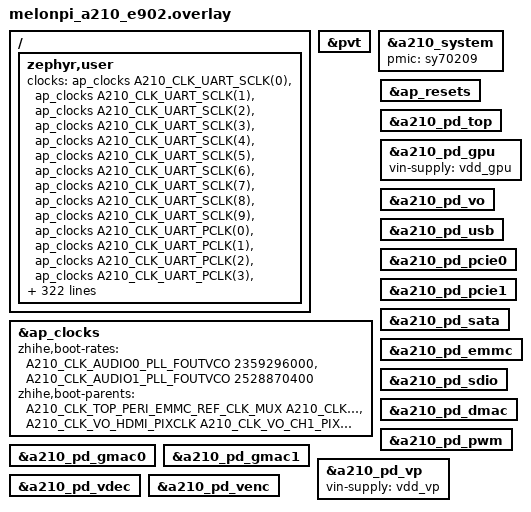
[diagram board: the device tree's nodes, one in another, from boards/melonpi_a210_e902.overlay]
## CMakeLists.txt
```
# SPDX-License-Identifier: Apache-2.0
cmake_minimum_required(VERSION 3.20.0)
find_package(Zephyr REQUIRED HINTS $ENV{ZEPHYR_BASE})
project(scmi_server)
target_sources(app PRIVATE src/main.c)
if(CONFIG_CLOCK_CONTROL_A210)
  target_sources(app PRIVATE src/a210_resources.c)
else()
  target_sources(app PRIVATE src/resources.c)
endif()
```

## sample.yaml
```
sample:
  name: SCMI platform server
tests:
  sample.subsys.scmi_server:
    build_only: true
    platform_allow:
      - light_val_a/th1520/e902
      - beaglev_ahead/th1520/e902
      - milkv_meles/th1520/e902
      - licheepi_4a/th1520/e902
      - melonpi/a210/e902
    tags: [scmi, regulator]
  sample.subsys.scmi_server.base:
    build_only: true
    platform_allow: [beaglev_ahead/th1520/e902]
    extra_configs: [CONFIG_SCMI_SERVER_VOLTAGE=n]
    tags: [scmi]
```

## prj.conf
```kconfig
CONFIG_MULTITHREADING=n
CONFIG_SYS_CLOCK_EXISTS=n
CONFIG_TIMESLICING=n
CONFIG_CONSOLE=n
CONFIG_SERIAL=n
CONFIG_PRINTK=n
CONFIG_BOOT_BANNER=n
CONFIG_LOG=n
CONFIG_ASSERT=y
CONFIG_ASSERT_MODULE_DEFAULT_LEVEL_NORMAL=y
CONFIG_DEVICE_API_ASSERT=n
CONFIG_MINIMAL_LIBC=y
CONFIG_SIZE_OPTIMIZATIONS=y
CONFIG_ISR_STACK_SIZE=4096
CONFIG_MAIN_STACK_SIZE=4096
CONFIG_HEAP_MEM_POOL_SIZE=0
CONFIG_BUILD_OUTPUT_BIN=y
CONFIG_BUILD_OUTPUT_HEX=n
CONFIG_COUNTER=y
CONFIG_I2C=y
CONFIG_REGULATOR=y
CONFIG_MBOX=y
CONFIG_SCMI_SERVER=y
CONFIG_SCMI_SERVER_PERFORMANCE=y
CONFIG_CLOCK_CONTROL=y
```

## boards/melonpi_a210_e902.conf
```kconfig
# SPDX-License-Identifier: Apache-2.0
CONFIG_SCMI_SERVER_CLOCK=y
CONFIG_SCMI_SERVER_RESET=y
CONFIG_RESET=y
CONFIG_POWER_DOMAIN=y
CONFIG_PM_DEVICE=y
CONFIG_SCMI_SERVER_POWER=y
CONFIG_SENSOR=y
CONFIG_SCMI_SERVER_SENSOR=y
CONFIG_SCMI_SERVER_SYSTEM_POWER=y
# Measured peaks on Melon Pi: 1024 bytes main, 32 bytes interrupt stack,
# from reset through Linux runtime, DVFS and power-domain tests.
CONFIG_MAIN_STACK_SIZE=2048
CONFIG_ISR_STACK_SIZE=1024
```

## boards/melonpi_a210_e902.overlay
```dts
/* SPDX-License-Identifier: Apache-2.0 */
#include <zephyr/dt-bindings/clock/zhihe-a210.h>
#include <zephyr/dt-bindings/reset/zhihe-a210.h>

&pvt {
	status = "okay";
};

&a210_system {
	pmic = <&sy70209>;
	status = "okay";
};

&ap_clocks {
	zhihe,boot-rates = <A210_CLK_AUDIO0_PLL_FOUTVCO 2359296000>,
			   <A210_CLK_AUDIO1_PLL_FOUTVCO 2528870400>;
	zhihe,boot-parents = <A210_CLK_TOP_PERI_EMMC_REF_CLK_MUX A210_CLK_AUDIO0_PLL_FOUTVCO>,
			     <A210_CLK_VO_HDMI_PIXCLK A210_CLK_VO_CH1_PIXCLK_EN>;
	status = "okay";
};

&ap_resets {
	status = "okay";
};

/ {
	zephyr,user {
		clocks = <&ap_clocks A210_CLK_UART_SCLK(0)>,
			 <&ap_clocks A210_CLK_UART_SCLK(1)>,
			 <&ap_clocks A210_CLK_UART_SCLK(2)>,
			 <&ap_clocks A210_CLK_UART_SCLK(3)>,
			 <&ap_clocks A210_CLK_UART_SCLK(4)>,
			 <&ap_clocks A210_CLK_UART_SCLK(5)>,
			 <&ap_clocks A210_CLK_UART_SCLK(6)>,
			 <&ap_clocks A210_CLK_UART_SCLK(7)>,
			 <&ap_clocks A210_CLK_UART_SCLK(8)>,
			 <&ap_clocks A210_CLK_UART_SCLK(9)>,
			 <&ap_clocks A210_CLK_UART_PCLK(0)>,
			 <&ap_clocks A210_CLK_UART_PCLK(1)>,
			 <&ap_clocks A210_CLK_UART_PCLK(2)>,
			 <&ap_clocks A210_CLK_UART_PCLK(3)>,
			 <&ap_clocks A210_CLK_UART_PCLK(4)>,
			 <&ap_clocks A210_CLK_UART_PCLK(5)>,
			 <&ap_clocks A210_CLK_UART_PCLK(6)>,
			 <&ap_clocks A210_CLK_UART_PCLK(7)>,
			 <&ap_clocks A210_CLK_UART_PCLK(8)>,
			 <&ap_clocks A210_CLK_UART_PCLK(9)>,
			 <&ap_clocks A210_CLK_PERI1_PAD>,
			 <&ap_clocks A210_CLK_PERI2_PAD>,
			 <&ap_clocks A210_CLK_PERI3_PAD>,
			 <&ap_clocks A210_CLK_AON_SYS>,
			 <&ap_clocks A210_CLK_AON_I2C1_IC>,
			 <&ap_clocks A210_CLK_AON_I2C1_PCLK>,
			 <&ap_clocks A210_CLK_AUDIO0_PLL_FOUTVCO>,
			 <&ap_clocks A210_CLK_AUDIO1_PLL_FOUTVCO>,
			 <&ap_clocks A210_CLK_TOP_GPU_CORE_CLK_DIV>,
			 <&ap_clocks A210_CLK_TOP_PERI_EMMC_REF_CLK_DIV>,
			 <&ap_clocks A210_CLK_TOP_PERI_EMMC_REF_CLK_MUX>,
			 <&ap_clocks A210_CLK_SW_PWR_WRAP_GPU_SYS_CLK_EN>,
			 <&ap_clocks A210_CLK_SW_PWR_WRAP_DFMU_CORE_CLK_EN>,
			 <&ap_clocks A210_CLK_SW_PWR_WRAP_GPU_CORE_CLK_EN>,
			 <&ap_clocks A210_CLK_E16PHY_PCLK_EN>,
			 <&ap_clocks A210_CLK_SATA_MST_AFENCE_ACLK_EN>,
			 <&ap_clocks A210_CLK_SATA_SLV_AFENCE_ACLK_EN>,
			 <&ap_clocks A210_CLK_SATA_GEN3X2_ACLK_EN>,
			 <&ap_clocks A210_CLK_X2X_SATA_SLV_ACLK_EN>,
			 <&ap_clocks A210_CLK_X2X_SATA_MST_ACLK_EN>,
			 <&ap_clocks A210_CLK_SATA_RXOOB1_CLK_EN>,
			 <&ap_clocks A210_CLK_SATA_RXOOB0_CLK_EN>,
			 <&ap_clocks A210_CLK_SATA_PMALIVE_CLK_EN>,
			 <&ap_clocks A210_CLK_PCIE_DM_GEN3X4_AUX_CLK_EN>,
			 <&ap_clocks A210_CLK_PCIE_DM_GEN3X4_MST_ACLK_EN>,
			 <&ap_clocks A210_CLK_PCIE_DM_GEN3X4_PCLK_EN>,
			 <&ap_clocks A210_CLK_PCIE_DM_GEN3X4_SLV_ACLK_EN>,
			 <&ap_clocks A210_CLK_PCIE_RP_GEN3X1_AUX_CLK_EN>,
			 <&ap_clocks A210_CLK_PCIE_RP_GEN3X1_MST_ACLK_EN>,
			 <&ap_clocks A210_CLK_PCIE_RP_GEN3X1_PCLK_EN>,
			 <&ap_clocks A210_CLK_PCIE_RP_GEN3X1_SLV_ACLK_EN>,
			 <&ap_clocks A210_CLK_USB_SS_AXI_MST_PCLK_EN>,
			 <&ap_clocks A210_CLK_USB_SS_AXI_MST_ACLK_EN>,
			 <&ap_clocks A210_CLK_USB_SS_DFMU_IOMMU_PTW_ACLK_EN>,
			 <&ap_clocks A210_CLK_USB_SS_DFMU_ACLK_EN>,
			 <&ap_clocks A210_CLK_USB_SS_DFMU_PCLK_EN>,
			 <&ap_clocks A210_CLK_USB31_SLV_AFENCE_ACLK_EN>,
			 <&ap_clocks A210_CLK_USB31_REF_CLK_EN>,
			 <&ap_clocks A210_CLK_USB31_SUSPEND_CLK_EN>,
			 <&ap_clocks A210_CLK_USB31_BUS_CLK_EN>,
			 <&ap_clocks A210_CLK_USB31_PCLK_EN>,
			 <&ap_clocks A210_CLK_C10PHY_SUSPEND_CLK_EN>,
			 <&ap_clocks A210_CLK_C10PHY_PCLK_EN>,
			 <&ap_clocks A210_CLK_VO_X2H1_CLK_EN>,
			 <&ap_clocks A210_CLK_VO_X2H0_CLK_EN>,
			 <&ap_clocks A210_CLK_VO_PTW_ACLK_EN>,
			 <&ap_clocks A210_CLK_VO_DFMU_ACLK_EN>,
			 <&ap_clocks A210_CLK_VO_DFMU_PCLK_EN>,
			 <&ap_clocks A210_CLK_VO_ARB_ACLK_EN>,
			 <&ap_clocks A210_CLK_VO_ARB_PCLK_EN>,
			 <&ap_clocks A210_CLK_VO_HDMI_SFRCLK_EN>,
			 <&ap_clocks A210_CLK_VO_CEC_CLK_EN>,
			 <&ap_clocks A210_CLK_VO_HDMI_PCLK_EN>,
			 <&ap_clocks A210_CLK_VO_DPU_ACLK_EN>,
			 <&ap_clocks A210_CLK_VO_DPUC_CLK_EN>,
			 <&ap_clocks A210_CLK_VO_DPU_HCLK_EN>,
			 <&ap_clocks A210_CLK_VO_CH1_PIXCLK_EN>,
			 <&ap_clocks A210_CLK_VO_CH0_PIXCLK_EN>,
			 <&ap_clocks A210_CLK_PERI0_MBOX1_PCLK_EN>,
			 <&ap_clocks A210_CLK_PERI0_MBOX0_PCLK_EN>,
			 <&ap_clocks A210_CLK_PERI0_WDT0_PCLK_EN>,
			 <&ap_clocks A210_CLK_PERI0_TIMER1_PCLK_EN>,
			 <&ap_clocks A210_CLK_PERI0_TIMER1_CCLK_EN>,
			 <&ap_clocks A210_CLK_PERI0_TIMER0_PCLK_EN>,
			 <&ap_clocks A210_CLK_PERI0_TIMER0_CCLK_EN>,
			 <&ap_clocks A210_CLK_PERI1_SPI0_SSI_CLK_EN>,
			 <&ap_clocks A210_CLK_PERI1_SPI0_PCLK_EN>,
			 <&ap_clocks A210_CLK_PERI1_QSPI0_SSI_CLK_EN>,
			 <&ap_clocks A210_CLK_PERI1_QSPI0_PCLK_EN>,
			 <&ap_clocks A210_CLK_PERI1_PWM0_CCLK_EN>,
			 <&ap_clocks A210_CLK_PERI1_I2C2_PCLK_EN>,
			 <&ap_clocks A210_CLK_PERI1_I2C2_IC_CLK_EN>,
			 <&ap_clocks A210_CLK_PERI1_I2C1_PCLK_EN>,
			 <&ap_clocks A210_CLK_PERI1_I2C1_IC_CLK_EN>,
			 <&ap_clocks A210_CLK_PERI1_I2C0_PCLK_EN>,
			 <&ap_clocks A210_CLK_PERI1_I2C0_IC_CLK_EN>,
			 <&ap_clocks A210_CLK_PERI1_GPIO1_PCLK_EN>,
			 <&ap_clocks A210_CLK_PERI1_GPIO1_DBCLK_EN>,
			 <&ap_clocks A210_CLK_PERI1_GPIO0_PCLK_EN>,
			 <&ap_clocks A210_CLK_PERI1_GPIO0_DBCLK_EN>,
			 <&ap_clocks A210_CLK_PERI1_GMAC1_HCLK_EN>,
			 <&ap_clocks A210_CLK_PERI1_GMAC1_ACLK_EN>,
			 <&ap_clocks A210_CLK_PERI1_GMAC0_HCLK_EN>,
			 <&ap_clocks A210_CLK_PERI1_GMAC0_ACLK_EN>,
			 <&ap_clocks A210_CLK_PERI2_I2S1_PCLK_EN>,
			 <&ap_clocks A210_CLK_PERI2_I2S1_SRC_CLK_EN>,
			 <&ap_clocks A210_CLK_PERI2_I2C7_IC_CLK_EN>,
			 <&ap_clocks A210_CLK_PERI2_I2C7_PCLK_EN>,
			 <&ap_clocks A210_CLK_PERI2_I2C6_IC_CLK_EN>,
			 <&ap_clocks A210_CLK_PERI2_I2C6_PCLK_EN>,
			 <&ap_clocks A210_CLK_PERI2_I2C5_IC_CLK_EN>,
			 <&ap_clocks A210_CLK_PERI2_I2C5_PCLK_EN>,
			 <&ap_clocks A210_CLK_PERI2_I2C4_IC_CLK_EN>,
			 <&ap_clocks A210_CLK_PERI2_I2C4_PCLK_EN>,
			 <&ap_clocks A210_CLK_PERI2_I2C3_IC_CLK_EN>,
			 <&ap_clocks A210_CLK_PERI2_I2C3_PCLK_EN>,
			 <&ap_clocks A210_CLK_PERI2_GPIO3_DBCLK_EN>,
			 <&ap_clocks A210_CLK_PERI2_GPIO3_PCLK_EN>,
			 <&ap_clocks A210_CLK_PERI2_SPI1_PCLK_EN>,
			 <&ap_clocks A210_CLK_PERI2_GPIO2_PCLK_EN>,
			 <&ap_clocks A210_CLK_PERI2_SPI1_SSI_CLK_EN>,
			 <&ap_clocks A210_CLK_PERI2_GPIO2_DBCLK_EN>,
			 <&ap_clocks A210_CLK_PERI2_QSPI1_PCLK_EN>,
			 <&ap_clocks A210_CLK_PERI2_QSPI1_SSI_CLK_EN>,
			 <&ap_clocks A210_CLK_PERI2_PWM2_CCLK_EN>,
			 <&ap_clocks A210_CLK_PERI2_PWM1_CCLK_EN>,
			 <&ap_clocks A210_CLK_PERI3_GPIO4_PCLK_EN>,
			 <&ap_clocks A210_CLK_PERI3_GPIO4_DBCLK_EN>,
			 <&ap_clocks A210_CLK_PERI3_ADC_PCLK_EN>,
			 <&ap_clocks A210_CLK_AXI_PERI3_MST_PCLK_EN>,
			 <&ap_clocks A210_CLK_AXI_PERI3_MST_ACLK_EN>,
			 <&ap_clocks A210_CLK_PERI3_SDIO_X2X_ACLK_S_EN>,
			 <&ap_clocks A210_CLK_PERI3_SDIO_X2X_ACLK_M_EN>,
			 <&ap_clocks A210_CLK_PERI3_SDIO_OSC_CLK_EN>,
			 <&ap_clocks A210_CLK_PERI3_SDIO_HCLK_EN>,
			 <&ap_clocks A210_CLK_PERI3_EMMC_X2X_ACLK_S_EN>,
			 <&ap_clocks A210_CLK_PERI3_EMMC_X2X_ACLK_M_EN>,
			 <&ap_clocks A210_CLK_PERI3_EMMC_OSC_CLK_EN>,
			 <&ap_clocks A210_CLK_PERI3_EMMC_HCLK_EN>,
			 <&ap_clocks A210_CLK_PERI3_EMMC_ACLK_EN>,
			 <&ap_clocks A210_CLK_PERI3_EMMC_SDIO_REF_CLK_CG_EN>,
			 <&ap_clocks A210_CLK_PERI3_DMAC_HCLK_EN>,
			 <&ap_clocks A210_CLK_PERI3_DMAC_ACLK_EN>,
			 <&ap_clocks A210_CLK_TEE_DMAC_CLKEN>,
			 <&ap_clocks A210_CLK_USB20_BUS_CLK>,
			 <&ap_clocks A210_CLK_PERI3_SDIO_ACLK_EN>,
			 <&ap_clocks A210_CLK_PERI1_X2H_GMAC1_HCLK_EN>,
			 <&ap_clocks A210_CLK_PERI1_X2H_GMAC1_ACLK_EN>,
			 <&ap_clocks A210_CLK_PERI1_X2H_GMAC0_HCLK_EN>,
			 <&ap_clocks A210_CLK_PERI1_X2H_GMAC0_ACLK_EN>,
			 <&ap_clocks A210_CLK_VO_HDMI_PIXCLK>,
			 <&ap_clocks A210_CLK_USB20_X2H_HCLK>,
			 <&ap_clocks A210_CLK_USB20_X2H_ACLK>,
			 <&ap_clocks A210_CLK_USB20_SLV_AFENCE_ACLK>,
			 <&ap_clocks A210_CLK_USB20_H2P_HCLK>,
			 <&ap_clocks A210_CLK_USB20_AHB_SLV_HCLK>,
			 <&ap_clocks A210_CLK_USB20_SYSREG_PCLK>,
			 <&ap_clocks A210_CLK_USB20_WRAP0_HCLK>,
			 <&ap_clocks A210_CLK_USB20_WRAP1_HCLK>,
			 <&ap_clocks A210_CLK_USB20_A2X0_HCLK>,
			 <&ap_clocks A210_CLK_USB20_A2X0_ACLK>,
			 <&ap_clocks A210_CLK_USB20_A2X1_HCLK>,
			 <&ap_clocks A210_CLK_USB20_A2X1_ACLK>,
			 <&ap_clocks A210_CLK_VP_VDEC_ACLK_EN>,
			 <&ap_clocks A210_CLK_VP_VDEC_CCLK_EN>,
			 <&ap_clocks A210_CLK_VP_VDEC_PCLK_EN>,
			 <&ap_clocks A210_CLK_VP_VENC_ACLK_EN>,
			 <&ap_clocks A210_CLK_VP_VENC_CCLK_EN>,
			 <&ap_clocks A210_CLK_VP_VENC_PCLK_EN>;
		resets = <&ap_resets A210_RESET_UART_SRST(0)>,
			 <&ap_resets A210_RESET_UART_SRST(1)>,
			 <&ap_resets A210_RESET_UART_SRST(2)>,
			 <&ap_resets A210_RESET_UART_SRST(3)>,
			 <&ap_resets A210_RESET_UART_SRST(4)>,
			 <&ap_resets A210_RESET_UART_SRST(5)>,
			 <&ap_resets A210_RESET_UART_SRST(6)>,
			 <&ap_resets A210_RESET_UART_SRST(7)>,
			 <&ap_resets A210_RESET_UART_SRST(8)>,
			 <&ap_resets A210_RESET_UART_SRST(9)>,
			 <&ap_resets A210_RESET_UART_PRST(0)>,
			 <&ap_resets A210_RESET_UART_PRST(1)>,
			 <&ap_resets A210_RESET_UART_PRST(2)>,
			 <&ap_resets A210_RESET_UART_PRST(3)>,
			 <&ap_resets A210_RESET_UART_PRST(4)>,
			 <&ap_resets A210_RESET_UART_PRST(5)>,
			 <&ap_resets A210_RESET_UART_PRST(6)>,
			 <&ap_resets A210_RESET_UART_PRST(7)>,
			 <&ap_resets A210_RESET_UART_PRST(8)>,
			 <&ap_resets A210_RESET_UART_PRST(9)>,
			 <&ap_resets A210_RESET_PERI1_PAD>,
			 <&ap_resets A210_RESET_PERI2_PAD>,
			 <&ap_resets A210_RESET_PERI3_PAD>,
			 <&ap_resets A210_RESET_AON_I2C1>,
			 <&ap_resets A210_RESET_GPU_PWR_WRAP_RGX_HOOD_RST>,
			 <&ap_resets A210_RESET_PCIE_DM_GEN3X4_APBS_PRST>,
			 <&ap_resets A210_RESET_PCIE_DM_GEN3X4_POWER_UP_RST>,
			 <&ap_resets A210_RESET_PCIE_E16PHY_APBS_PRST>,
			 <&ap_resets A210_RESET_PCIE_E16PHY_PHY_RST>,
			 <&ap_resets A210_RESET_PCIE_RP_GEN3X1_APBS_PRST>,
			 <&ap_resets A210_RESET_PCIE_RP_GEN3X1_POWER_UP_RST>,
			 <&ap_resets A210_RESET_PCIE_SATA_ARESET>,
			 <&ap_resets A210_RESET_PCIE_SATA_MST_AFENCE_ARST>,
			 <&ap_resets A210_RESET_PCIE_SATA_RST_ASIC0>,
			 <&ap_resets A210_RESET_PCIE_SATA_RST_ASIC1>,
			 <&ap_resets A210_RESET_PCIE_SATA_RST_PMALIVE>,
			 <&ap_resets A210_RESET_PCIE_SATA_RST_RXOOB0>,
			 <&ap_resets A210_RESET_PCIE_SATA_RST_RXOOB1>,
			 <&ap_resets A210_RESET_PCIE_SATA_SLV_AFENCE_ARST>,
			 <&ap_resets A210_RESET_PCIE_X2X_SATA_MST_ARST>,
			 <&ap_resets A210_RESET_PCIE_X2X_SATA_SLV_ARST>,
			 <&ap_resets A210_RESET_PERI0_TIMER0_CRST>,
			 <&ap_resets A210_RESET_PERI0_TIMER0_PRST>,
			 <&ap_resets A210_RESET_PERI0_TIMER1_CRST>,
			 <&ap_resets A210_RESET_PERI0_TIMER1_PRST>,
			 <&ap_resets A210_RESET_PERI0_WDT0_PRST>,
			 <&ap_resets A210_RESET_PERI1_GMAC0_ARST>,
			 <&ap_resets A210_RESET_PERI1_GMAC0_HRST>,
			 <&ap_resets A210_RESET_PERI1_GMAC0_X2H_ARST>,
			 <&ap_resets A210_RESET_PERI1_GMAC0_X2H_HRST>,
			 <&ap_resets A210_RESET_PERI1_GMAC1_ARST>,
			 <&ap_resets A210_RESET_PERI1_GMAC1_HRST>,
			 <&ap_resets A210_RESET_PERI1_GMAC1_X2H_ARST>,
			 <&ap_resets A210_RESET_PERI1_GMAC1_X2H_HRST>,
			 <&ap_resets A210_RESET_PERI1_GPIO0_DBRST>,
			 <&ap_resets A210_RESET_PERI1_GPIO0_PRST>,
			 <&ap_resets A210_RESET_PERI1_GPIO1_DBRST>,
			 <&ap_resets A210_RESET_PERI1_GPIO1_PRST>,
			 <&ap_resets A210_RESET_PERI1_I2C0_IC_RST>,
			 <&ap_resets A210_RESET_PERI1_I2C0_PRST>,
			 <&ap_resets A210_RESET_PERI1_I2C1_IC_RST>,
			 <&ap_resets A210_RESET_PERI1_I2C1_PRST>,
			 <&ap_resets A210_RESET_PERI1_I2C2_IC_RST>,
			 <&ap_resets A210_RESET_PERI1_I2C2_PRST>,
			 <&ap_resets A210_RESET_PERI1_PWM0_CRST>,
			 <&ap_resets A210_RESET_PERI1_PWM0_PRST>,
			 <&ap_resets A210_RESET_PERI1_QSPI0_PRST>,
			 <&ap_resets A210_RESET_PERI1_QSPI0_SSI_RST>,
			 <&ap_resets A210_RESET_PERI1_SPI0_PRST>,
			 <&ap_resets A210_RESET_PERI1_SPI0_SSI_RST>,
			 <&ap_resets A210_RESET_PERI2_GPIO2_DBRST>,
			 <&ap_resets A210_RESET_PERI2_GPIO2_PRST>,
			 <&ap_resets A210_RESET_PERI2_GPIO3_DBRST>,
			 <&ap_resets A210_RESET_PERI2_GPIO3_PRST>,
			 <&ap_resets A210_RESET_PERI2_I2C3_IC_RST>,
			 <&ap_resets A210_RESET_PERI2_I2C3_PRST>,
			 <&ap_resets A210_RESET_PERI2_I2C4_IC_RST>,
			 <&ap_resets A210_RESET_PERI2_I2C4_PRST>,
			 <&ap_resets A210_RESET_PERI2_I2C5_IC_RST>,
			 <&ap_resets A210_RESET_PERI2_I2C5_PRST>,
			 <&ap_resets A210_RESET_PERI2_I2C6_IC_RST>,
			 <&ap_resets A210_RESET_PERI2_I2C6_PRST>,
			 <&ap_resets A210_RESET_PERI2_I2C7_IC_RST>,
			 <&ap_resets A210_RESET_PERI2_I2C7_PRST>,
			 <&ap_resets A210_RESET_PERI2_I2S1_PRST>,
			 <&ap_resets A210_RESET_PERI2_PWM1_CRST>,
			 <&ap_resets A210_RESET_PERI2_PWM1_PRST>,
			 <&ap_resets A210_RESET_PERI2_PWM2_CRST>,
			 <&ap_resets A210_RESET_PERI2_PWM2_PRST>,
			 <&ap_resets A210_RESET_PERI2_QSPI1_PRST>,
			 <&ap_resets A210_RESET_PERI2_QSPI1_SSI_RST>,
			 <&ap_resets A210_RESET_PERI2_SPI1_PRST>,
			 <&ap_resets A210_RESET_PERI2_SPI1_SSI_RST>,
			 <&ap_resets A210_RESET_PERI3_ADC_PRST>,
			 <&ap_resets A210_RESET_PERI3_DMAC_ARST>,
			 <&ap_resets A210_RESET_PERI3_DMAC_HRST>,
			 <&ap_resets A210_RESET_PERI3_EMMC_RST>,
			 <&ap_resets A210_RESET_PERI3_EMMC_X2X_ARST_M>,
			 <&ap_resets A210_RESET_PERI3_EMMC_X2X_ARST_S>,
			 <&ap_resets A210_RESET_PERI3_GPIO4_DBRST>,
			 <&ap_resets A210_RESET_PERI3_GPIO4_PRST>,
			 <&ap_resets A210_RESET_PERI3_SDIO_RST>,
			 <&ap_resets A210_RESET_PERI3_SDIO_X2X_ARST_M>,
			 <&ap_resets A210_RESET_PERI3_SDIO_X2X_ARST_S>,
			 <&ap_resets A210_RESET_TEE_DMAC_ARST>,
			 <&ap_resets A210_RESET_TEE_DMAC_HRST>,
			 <&ap_resets A210_RESET_USB_AXI4_MST_ARST>,
			 <&ap_resets A210_RESET_USB_AXI4_MST_PRST>,
			 <&ap_resets A210_RESET_USB_C10PHY_APBS_PRST>,
			 <&ap_resets A210_RESET_USB_C10PHY_PHY_RST>,
			 <&ap_resets A210_RESET_USB_DFMU_ARST>,
			 <&ap_resets A210_RESET_USB_DFMU_PRST>,
			 <&ap_resets A210_RESET_USB_USB20_BLK_A2X0_ARST>,
			 <&ap_resets A210_RESET_USB_USB20_BLK_A2X0_HRST>,
			 <&ap_resets A210_RESET_USB_USB20_BLK_A2X1_ARST>,
			 <&ap_resets A210_RESET_USB_USB20_BLK_A2X1_HRST>,
			 <&ap_resets A210_RESET_USB_USB20_BLK_AHB_SLV_HRST>,
			 <&ap_resets A210_RESET_USB_USB20_BLK_AXI_MST_ARST>,
			 <&ap_resets A210_RESET_USB_USB20_BLK_H2P_HRST>,
			 <&ap_resets A210_RESET_USB_USB20_BLK_USB0_PHY_PON_RESET>,
			 <&ap_resets A210_RESET_USB_USB20_BLK_USB1_PHY_PON_RESET>,
			 <&ap_resets A210_RESET_USB_USB20_BLK_USB2_SYSREG_PRST>,
			 <&ap_resets A210_RESET_USB_USB20_BLK_USB2_WRAP0_HRST>,
			 <&ap_resets A210_RESET_USB_USB20_BLK_USB2_WRAP0_PRST>,
			 <&ap_resets A210_RESET_USB_USB20_BLK_USB2_WRAP1_HRST>,
			 <&ap_resets A210_RESET_USB_USB20_BLK_USB2_WRAP1_PRST>,
			 <&ap_resets A210_RESET_USB_USB20_BLK_X2H_ARST>,
			 <&ap_resets A210_RESET_USB_USB20_BLK_X2H_HRST>,
			 <&ap_resets A210_RESET_USB_USB20_SLV_AFENCE_ARST>,
			 <&ap_resets A210_RESET_USB_USB31_APBS_PRST>,
			 <&ap_resets A210_RESET_USB_USB31_PHY_RST>,
			 <&ap_resets A210_RESET_USB_USB31_SLV_AFENCE_ARST>,
			 <&ap_resets A210_RESET_USB_USB31_VCC_RST>,
			 <&ap_resets A210_RESET_VO_ARB_ARST>,
			 <&ap_resets A210_RESET_VO_ARB_PRST>,
			 <&ap_resets A210_RESET_VO_DFMU_ARST>,
			 <&ap_resets A210_RESET_VO_DFMU_PRST>,
			 <&ap_resets A210_RESET_VO_DPU_ARST>,
			 <&ap_resets A210_RESET_VO_DPU_CRST>,
			 <&ap_resets A210_RESET_VO_DPU_HRST>,
			 <&ap_resets A210_RESET_VO_HDMI_MAIN_RST>,
			 <&ap_resets A210_RESET_VO_HDMI_PRST>,
			 <&ap_resets A210_RESET_VO_X2H0_RST>,
			 <&ap_resets A210_RESET_VO_X2H1_RST>,
			 <&ap_resets A210_RESET_VP_VDEC_PRST>,
			 <&ap_resets A210_RESET_VP_VDEC_CRST>,
			 <&ap_resets A210_RESET_VP_VDEC_ARST>,
			 <&ap_resets A210_RESET_VP_VENC_PRST>,
			 <&ap_resets A210_RESET_VP_VENC_CRST>,
			 <&ap_resets A210_RESET_VP_VENC_ARST>,
			 <&ap_resets A210_RESET_VP_COMP_PRST>,
			 <&ap_resets A210_RESET_VP_COMP_CRST>,
			 <&ap_resets A210_RESET_VP_COMP_ARST>,
			 <&ap_resets A210_RESET_VP_DECOMP_PRST>,
			 <&ap_resets A210_RESET_VP_DECOMP_CRST>,
			 <&ap_resets A210_RESET_VP_DECOMP_ARST>,
			 <&ap_resets A210_RESET_VP_COMP_EXTPRST>,
			 <&ap_resets A210_RESET_VP_DECOMP_EXTPRST>;
	};
};

&a210_pd_top {
	status = "okay";
};

&a210_pd_gpu {
	vin-supply = <&vdd_gpu>;
	status = "okay";
};

&a210_pd_vo {
	status = "okay";
};

&a210_pd_usb {
	status = "okay";
};

&a210_pd_pcie0 {
	status = "okay";
};

&a210_pd_pcie1 {
	status = "okay";
};

&a210_pd_sata {
	status = "okay";
};

&a210_pd_emmc {
	status = "okay";
};

&a210_pd_sdio {
	status = "okay";
};

&a210_pd_dmac {
	status = "okay";
};

&a210_pd_pwm {
	status = "okay";
};

&a210_pd_gmac0 {
	status = "okay";
};

&a210_pd_gmac1 {
	status = "okay";
};

&a210_pd_vp {
	vin-supply = <&vdd_vp>;
	status = "okay";
};

&a210_pd_vdec {
	status = "okay";
};

&a210_pd_venc {
	status = "okay";
};

/ {
	zephyr,user {
		power-domains = <&a210_pd_top>,
				<&a210_pd_gpu>,
				<&a210_pd_vo>,
				<&a210_pd_usb>,
				<&a210_pd_pcie0>,
				<&a210_pd_pcie1>,
				<&a210_pd_sata>,
				<&a210_pd_emmc>,
				<&a210_pd_sdio>,
				<&a210_pd_dmac>,
				<&a210_pd_pwm>,
				<&a210_pd_gmac0>,
				<&a210_pd_gmac1>,
				<&a210_pd_vdec>,
				<&a210_pd_venc>;
		read-only-voltage-domains = <&vdd_cpu &vddm_cpu &vdd_cpu_p &vdd_gpu &vdd_vp>;
		/* Vendor AON firmware powers off at the 125 C PVT alarm. */
		zhihe,critical-millicelsius = <125000>;
	};
};
```

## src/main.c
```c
/* SPDX-License-Identifier: Apache-2.0 */
#include <zephyr/kernel.h>
#include <zephyr/drivers/clock_control.h>
#include <zephyr/mgmt/scmi/performance.h>
#include <zephyr/drivers/mbox.h>
#include <zephyr/drivers/mbox/e902.h>
#include <zephyr/mgmt/scmi/regulator.h>
#include <zephyr/sys/sys_io.h>
#include "resources.h"

#define SHMEM   DT_CHOSEN(zephyr_scmi_shmem)
#define MAILBOX DT_CHOSEN(zephyr_scmi_mailbox)
#define USER    DT_PATH(zephyr_user)
BUILD_ASSERT(DT_REG_SIZE(SHMEM) == SCMI_SMT_SIZE);

static struct scmi_server server = {
	.identity = {.vendor = "Zephyr", .sub_vendor = CONFIG_SOC, .implementation_version = 5},
};
static const struct device *const mailbox = DEVICE_DT_GET(MAILBOX);
static uint32_t read_memory(void *ctx, size_t offset)
{
	ARG_UNUSED(ctx);
	return sys_read32(DT_REG_ADDR(SHMEM) + offset);
}
static void write_memory(void *ctx, size_t offset, uint32_t value)
{
	ARG_UNUSED(ctx);
	sys_write32(value, DT_REG_ADDR(SHMEM) + offset);
}
static void memory_barrier(void *ctx)
{
	ARG_UNUSED(ctx);
	/* Order device I/O as well as memory; a data-only fence is insufficient. */
	__asm__ volatile("fence iorw, iorw" ::: "memory");
}
static void notify(void *ctx)
{
	ARG_UNUSED(ctx);
	(void)mbox_send(mailbox, 0, NULL);
}
static const struct scmi_smt_io io = {
	.read32 = read_memory,
	.write32 = write_memory,
	.barrier = memory_barrier,
	.notify = notify,
};
static void receive(const struct device *dev, uint32_t channel, void *ctx, struct mbox_msg *msg)
{
	ARG_UNUSED(dev);
	ARG_UNUSED(channel);
	ARG_UNUSED(ctx);
	ARG_UNUSED(msg);
	(void)scmi_smt_respond(&io, &server);
}

#if defined(CONFIG_SCMI_SERVER_REGULATOR) && DT_NODE_HAS_PROP(USER, voltage_domains)
struct domain_config {
	const struct device *dev;
	const char *name;
	bool always_on;
};
#define DOMAIN(node, prop, idx)                                                                    \
	{DEVICE_DT_GET(DT_PHANDLE_BY_IDX(node, prop, idx)),                                        \
	 DT_PROP(DT_PHANDLE_BY_IDX(node, prop, idx), regulator_name),                              \
	 DT_PROP(DT_PHANDLE_BY_IDX(node, prop, idx), regulator_always_on)},
static const struct domain_config configs[] = {DT_FOREACH_PROP_ELEM(USER, voltage_domains, DOMAIN)};
static struct scmi_voltage_domain domains[ARRAY_SIZE(configs)];
#endif

#if defined(CONFIG_SCMI_SERVER_PERFORMANCE) && DT_NODE_HAS_PROP(USER, performance_domains)
#define PERF_OPP(node)                                                                             \
	{DT_PROP_BY_IDX(node, opp_hz, 1) / 1000, DT_PROP_BY_IDX(node, opp_hz, 1) / 1000, 10000},
#define PERF_LEVELS(node, prop, i)                                                                 \
	static const struct scmi_performance_level perf_levels_##i[] = {                           \
		DT_FOREACH_CHILD_STATUS_OKAY(                                                      \
			DT_PHANDLE(DT_PHANDLE_BY_IDX(node, prop, i), operating_points_v2),         \
			PERF_OPP)}
DT_FOREACH_PROP_ELEM_SEP(USER, performance_domains, PERF_LEVELS, (;));

static int perf_get(void *context, uint32_t *khz)
{
	uint32_t hz;
	int ret = clock_control_get_rate(context, NULL, &hz);

	if (!ret) {
		*khz = hz / 1000;
	}
	return ret;
}

static int perf_set(void *context, uint32_t khz)
{
	if (khz > UINT32_MAX / 1000) {
		return -ERANGE;
	}
	return clock_control_set_rate(context, NULL, (void *)(uintptr_t)(khz * 1000));
}

#define PERF_DOMAIN(node, prop, i)                                                                 \
	{                                                                                          \
		.name = DT_PROP(DT_PHANDLE_BY_IDX(node, prop, i), domain_name),                    \
		.levels = perf_levels_##i,                                                         \
		.count = ARRAY_SIZE(perf_levels_##i),                                              \
		.sustained_khz =                                                                   \
			DT_PROP(DT_PHANDLE_BY_IDX(node, prop, i), sustained_frequency_khz),        \
		.rate_limit_us = DT_PROP(DT_PHANDLE_BY_IDX(node, prop, i), transition_latency_us), \
		.get_level = perf_get,                                                             \
		.set_level = perf_set,                                                             \
		.context = (void *)DEVICE_DT_GET(DT_PHANDLE_BY_IDX(node, prop, i)),                \
	},
static const struct scmi_performance_domain performance_domains[] = {
	DT_FOREACH_PROP_ELEM(USER, performance_domains, PERF_DOMAIN)};
#endif

#if DT_NODE_HAS_PROP(USER, read_only_voltage_domains)
#define RO_DOMAIN(node, prop, i) DEVICE_DT_GET(DT_PHANDLE_BY_IDX(node, prop, i)),
static const struct device *const read_only_supplies[] = {
	DT_FOREACH_PROP_ELEM(USER, read_only_voltage_domains, RO_DOMAIN)};
#endif

int main(void)
{
	int ret = scmi_resources_init(&server);

	if (ret) {
		return ret;
	}
	if (!device_is_ready(mailbox)) {
		return -ENODEV;
	}
	(void)irq_lock();
#if defined(CONFIG_SCMI_SERVER_REGULATOR) && DT_NODE_HAS_PROP(USER, voltage_domains)
	for (size_t i = 0; i < ARRAY_SIZE(configs); i++) {
		(void)scmi_regulator_domain_init(&domains[i], configs[i].dev, configs[i].name,
						 configs[i].always_on);
	}
#if DT_NODE_HAS_PROP(USER, read_only_voltage_domains)
	for (size_t i = 0; i < ARRAY_SIZE(configs); i++) {
		for (size_t j = 0; j < ARRAY_SIZE(read_only_supplies); j++) {
			if (configs[i].dev == read_only_supplies[j]) {
				domains[i].read_only = true;
			}
		}
	}
#endif
	server.voltage_domains = domains;
	server.voltage_count = ARRAY_SIZE(domains);
#endif
#if defined(CONFIG_SCMI_SERVER_PERFORMANCE) && DT_NODE_HAS_PROP(USER, performance_domains)
	for (size_t i = 0; i < ARRAY_SIZE(performance_domains); i++) {
		if (!device_is_ready(performance_domains[i].context)) {
			return -ENODEV;
		}
	}
	server.performance_domains = performance_domains;
	server.performance_count = ARRAY_SIZE(performance_domains);
#endif
	scmi_smt_init(&io);
	mbox_register_callback(mailbox, 0, receive, NULL);
	if (mbox_set_enabled(mailbox, 0, true)) {
		return -EIO;
	}
	for (;;) {
		(void)mbox_e902_poll(mailbox);
		scmi_resources_poll();
	}
	return 0;
}
```

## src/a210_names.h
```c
/* SPDX-License-Identifier: Apache-2.0 */
#ifndef A210_NAMES_H_
#define A210_NAMES_H_

#include <stdint.h>
#include <zephyr/toolchain.h>
#include <zephyr/dt-bindings/clock/zhihe-a210.h>
#include <zephyr/dt-bindings/reset/zhihe-a210.h>

/* SCMI short names, including the terminating NUL. */
#define A210_NAME_SIZE 16

/*
 * SCMI clock and reset names: a block stem and an optional signal suffix,
 * joined by a hyphen. Underscores in the stems and suffixes are reported as
 * hyphens. Each string is stored once to fit the firmware RAM.
 */
#define NAME_STEMS(X)                                                                              \
	X(adc) X(aon_i2c1) X(aon_sys) X(audio0_pll) X(audio1_pll) X(c10phy) X(c10phy_susp)         \
	X(comp) X(comp_ext) X(decomp) X(decomp_ext) X(dmac) X(e16phy) X(emmc) X(emmc_osc)          \
	X(emmc_ref_div) X(emmc_ref_mux) X(emmc_sdio_ref) X(emmc_x2x) X(gmac0) X(gmac0_x2h)         \
	X(gmac1) X(gmac1_x2h) X(gpio0) X(gpio1) X(gpio2) X(gpio3) X(gpio4) X(gpu) X(gpu_core)      \
	X(gpu_core_div) X(gpu_dfmu) X(gpu_sys) X(i2c0) X(i2c1) X(i2c2) X(i2c3) X(i2c4) X(i2c5)     \
	X(i2c6) X(i2c7) X(i2s1) X(i2s1_src) X(mbox0) X(mbox1) X(pcie0) X(pcie0_aux)                \
	X(pcie0_mst) X(pcie0_pwrup) X(pcie0_slv) X(pcie1) X(pcie1_aux) X(pcie1_mst)                \
	X(pcie1_pwrup) X(pcie1_slv) X(peri1_pad) X(peri2_pad) X(peri3_axi) X(peri3_pad) X(pwm0)    \
	X(pwm1) X(pwm2) X(qspi0) X(qspi1) X(sata) X(sata_af) X(sata_asic0) X(sata_asic1)           \
	X(sata_pmalive) X(sata_rxoob0) X(sata_rxoob1) X(sata_x2x) X(sdio) X(sdio_osc)              \
	X(sdio_x2x) X(spi0) X(spi1) X(tee_dmac) X(timer0) X(timer1) X(uart0) X(uart1) X(uart2)     \
	X(uart3) X(uart4) X(uart5) X(uart6) X(uart7) X(uart8) X(uart9) X(usb2_a2x0)                \
	X(usb2_a2x1) X(usb2_af) X(usb2_ahb) X(usb2_axi) X(usb2_bus) X(usb2_h2p) X(usb2_phy0)       \
	X(usb2_phy1) X(usb2_sys) X(usb2_wrap0) X(usb2_wrap1) X(usb2_x2h) X(usb3) X(usb3_af)        \
	X(usb3_bus) X(usb3_ref) X(usb3_susp) X(usb3_vcc) X(usbss_axi) X(usbss_dfmu)                \
	X(usbss_ptw) X(vdec) X(venc) X(vo_arb) X(vo_cec) X(vo_ch0) X(vo_ch1) X(vo_dfmu)            \
	X(vo_dpu) X(vo_hdmi) X(vo_hdmi_sfrclk) X(vo_ptw) X(vo_x2h0) X(vo_x2h1) X(wdt0)

#define NAME_SUFFIXES(X)                                                                           \
	X(aclk) X(apb) X(arst) X(cclk) X(crst) X(dbclk) X(dbrst) X(hclk) X(hrst) X(ic)             \
	X(ic_rst) X(mst) X(pclk) X(phy) X(pixclk) X(prst) X(rst) X(slv) X(ssi) X(ssi_rst)

#define NAME_STEM(name)   STEM_##name,
#define NAME_SUFFIX(name) SUFFIX_##name,
#define NAME_STRING(name) #name "\0"

enum a210_name_stem {
	STEM_NONE,
	NAME_STEMS(NAME_STEM) STEM_COUNT
};

enum a210_name_suffix {
	SUFFIX_NONE,
	NAME_SUFFIXES(NAME_SUFFIX) SUFFIX_COUNT
};

static const char name_stems[] = NAME_STEMS(NAME_STRING);
static const char name_suffixes[] = NAME_SUFFIXES(NAME_STRING);

struct a210_name {
	uint8_t stem;
	uint8_t suffix;
};

BUILD_ASSERT(STEM_COUNT <= UINT8_MAX + 1 && SUFFIX_COUNT <= UINT8_MAX + 1);

#define NAME(stem, suffix) {STEM_##stem, SUFFIX_##suffix}

static const struct a210_name clock_names[] = {
	[A210_CLK_UART_SCLK(0)] = NAME(uart0, NONE),
	[A210_CLK_UART_SCLK(1)] = NAME(uart1, NONE),
	[A210_CLK_UART_SCLK(2)] = NAME(uart2, NONE),
	[A210_CLK_UART_SCLK(3)] = NAME(uart3, NONE),
	[A210_CLK_UART_SCLK(4)] = NAME(uart4, NONE),
	[A210_CLK_UART_SCLK(5)] = NAME(uart5, NONE),
	[A210_CLK_UART_SCLK(6)] = NAME(uart6, NONE),
	[A210_CLK_UART_SCLK(7)] = NAME(uart7, NONE),
	[A210_CLK_UART_SCLK(8)] = NAME(uart8, NONE),
	[A210_CLK_UART_SCLK(9)] = NAME(uart9, NONE),
	[A210_CLK_UART_PCLK(0)] = NAME(uart0, pclk),
	[A210_CLK_UART_PCLK(1)] = NAME(uart1, pclk),
	[A210_CLK_UART_PCLK(2)] = NAME(uart2, pclk),
	[A210_CLK_UART_PCLK(3)] = NAME(uart3, pclk),
	[A210_CLK_UART_PCLK(4)] = NAME(uart4, pclk),
	[A210_CLK_UART_PCLK(5)] = NAME(uart5, pclk),
	[A210_CLK_UART_PCLK(6)] = NAME(uart6, pclk),
	[A210_CLK_UART_PCLK(7)] = NAME(uart7, pclk),
	[A210_CLK_UART_PCLK(8)] = NAME(uart8, pclk),
	[A210_CLK_UART_PCLK(9)] = NAME(uart9, pclk),
	[A210_CLK_PERI1_PAD] = NAME(peri1_pad, NONE),
	[A210_CLK_PERI2_PAD] = NAME(peri2_pad, NONE),
	[A210_CLK_PERI3_PAD] = NAME(peri3_pad, NONE),
	[A210_CLK_AON_SYS] = NAME(aon_sys, NONE),
	[A210_CLK_AON_I2C1_IC] = NAME(aon_i2c1, ic),
	[A210_CLK_AON_I2C1_PCLK] = NAME(aon_i2c1, pclk),
	[A210_CLK_AUDIO0_PLL_FOUTVCO] = NAME(audio0_pll, NONE),
	[A210_CLK_AUDIO1_PLL_FOUTVCO] = NAME(audio1_pll, NONE),
	[A210_CLK_TOP_GPU_CORE_CLK_DIV] = NAME(gpu_core_div, NONE),
	[A210_CLK_TOP_PERI_EMMC_REF_CLK_DIV] = NAME(emmc_ref_div, NONE),
	[A210_CLK_TOP_PERI_EMMC_REF_CLK_MUX] = NAME(emmc_ref_mux, NONE),
	[A210_CLK_SW_PWR_WRAP_GPU_SYS_CLK_EN] = NAME(gpu_sys, NONE),
	[A210_CLK_SW_PWR_WRAP_DFMU_CORE_CLK_EN] = NAME(gpu_dfmu, NONE),
	[A210_CLK_SW_PWR_WRAP_GPU_CORE_CLK_EN] = NAME(gpu_core, NONE),
	[A210_CLK_E16PHY_PCLK_EN] = NAME(e16phy, pclk),
	[A210_CLK_SATA_MST_AFENCE_ACLK_EN] = NAME(sata_af, mst),
	[A210_CLK_SATA_SLV_AFENCE_ACLK_EN] = NAME(sata_af, slv),
	[A210_CLK_SATA_GEN3X2_ACLK_EN] = NAME(sata, aclk),
	[A210_CLK_X2X_SATA_SLV_ACLK_EN] = NAME(sata_x2x, slv),
	[A210_CLK_X2X_SATA_MST_ACLK_EN] = NAME(sata_x2x, mst),
	[A210_CLK_SATA_RXOOB1_CLK_EN] = NAME(sata_rxoob1, NONE),
	[A210_CLK_SATA_RXOOB0_CLK_EN] = NAME(sata_rxoob0, NONE),
	[A210_CLK_SATA_PMALIVE_CLK_EN] = NAME(sata_pmalive, NONE),
	[A210_CLK_PCIE_DM_GEN3X4_AUX_CLK_EN] = NAME(pcie0_aux, NONE),
	[A210_CLK_PCIE_DM_GEN3X4_MST_ACLK_EN] = NAME(pcie0_mst, aclk),
	[A210_CLK_PCIE_DM_GEN3X4_PCLK_EN] = NAME(pcie0, pclk),
	[A210_CLK_PCIE_DM_GEN3X4_SLV_ACLK_EN] = NAME(pcie0_slv, aclk),
	[A210_CLK_PCIE_RP_GEN3X1_AUX_CLK_EN] = NAME(pcie1_aux, NONE),
	[A210_CLK_PCIE_RP_GEN3X1_MST_ACLK_EN] = NAME(pcie1_mst, aclk),
	[A210_CLK_PCIE_RP_GEN3X1_PCLK_EN] = NAME(pcie1, pclk),
	[A210_CLK_PCIE_RP_GEN3X1_SLV_ACLK_EN] = NAME(pcie1_slv, aclk),
	[A210_CLK_USB_SS_AXI_MST_PCLK_EN] = NAME(usbss_axi, pclk),
	[A210_CLK_USB_SS_AXI_MST_ACLK_EN] = NAME(usbss_axi, aclk),
	[A210_CLK_USB_SS_DFMU_IOMMU_PTW_ACLK_EN] = NAME(usbss_ptw, aclk),
	[A210_CLK_USB_SS_DFMU_ACLK_EN] = NAME(usbss_dfmu, aclk),
	[A210_CLK_USB_SS_DFMU_PCLK_EN] = NAME(usbss_dfmu, pclk),
	[A210_CLK_USB31_SLV_AFENCE_ACLK_EN] = NAME(usb3_af, slv),
	[A210_CLK_USB31_REF_CLK_EN] = NAME(usb3_ref, NONE),
	[A210_CLK_USB31_SUSPEND_CLK_EN] = NAME(usb3_susp, NONE),
	[A210_CLK_USB31_BUS_CLK_EN] = NAME(usb3_bus, NONE),
	[A210_CLK_USB31_PCLK_EN] = NAME(usb3, pclk),
	[A210_CLK_C10PHY_SUSPEND_CLK_EN] = NAME(c10phy_susp, NONE),
	[A210_CLK_C10PHY_PCLK_EN] = NAME(c10phy, pclk),
	[A210_CLK_VO_X2H1_CLK_EN] = NAME(vo_x2h1, NONE),
	[A210_CLK_VO_X2H0_CLK_EN] = NAME(vo_x2h0, NONE),
	[A210_CLK_VO_PTW_ACLK_EN] = NAME(vo_ptw, aclk),
	[A210_CLK_VO_DFMU_ACLK_EN] = NAME(vo_dfmu, aclk),
	[A210_CLK_VO_DFMU_PCLK_EN] = NAME(vo_dfmu, pclk),
	[A210_CLK_VO_ARB_ACLK_EN] = NAME(vo_arb, aclk),
	[A210_CLK_VO_ARB_PCLK_EN] = NAME(vo_arb, pclk),
	[A210_CLK_VO_HDMI_SFRCLK_EN] = NAME(vo_hdmi_sfrclk, NONE),
	[A210_CLK_VO_CEC_CLK_EN] = NAME(vo_cec, NONE),
	[A210_CLK_VO_HDMI_PCLK_EN] = NAME(vo_hdmi, pclk),
	[A210_CLK_VO_DPU_ACLK_EN] = NAME(vo_dpu, aclk),
	[A210_CLK_VO_DPUC_CLK_EN] = NAME(vo_dpu, cclk),
	[A210_CLK_VO_DPU_HCLK_EN] = NAME(vo_dpu, hclk),
	[A210_CLK_VO_CH1_PIXCLK_EN] = NAME(vo_ch1, pixclk),
	[A210_CLK_VO_CH0_PIXCLK_EN] = NAME(vo_ch0, pixclk),
	[A210_CLK_PERI0_MBOX1_PCLK_EN] = NAME(mbox1, pclk),
	[A210_CLK_PERI0_MBOX0_PCLK_EN] = NAME(mbox0, pclk),
	[A210_CLK_PERI0_WDT0_PCLK_EN] = NAME(wdt0, pclk),
	[A210_CLK_PERI0_TIMER1_PCLK_EN] = NAME(timer1, pclk),
	[A210_CLK_PERI0_TIMER1_CCLK_EN] = NAME(timer1, cclk),
	[A210_CLK_PERI0_TIMER0_PCLK_EN] = NAME(timer0, pclk),
	[A210_CLK_PERI0_TIMER0_CCLK_EN] = NAME(timer0, cclk),
	[A210_CLK_PERI1_SPI0_SSI_CLK_EN] = NAME(spi0, ssi),
	[A210_CLK_PERI1_SPI0_PCLK_EN] = NAME(spi0, pclk),
	[A210_CLK_PERI1_QSPI0_SSI_CLK_EN] = NAME(qspi0, ssi),
	[A210_CLK_PERI1_QSPI0_PCLK_EN] = NAME(qspi0, pclk),
	[A210_CLK_PERI1_PWM0_CCLK_EN] = NAME(pwm0, cclk),
	[A210_CLK_PERI1_I2C2_PCLK_EN] = NAME(i2c2, pclk),
	[A210_CLK_PERI1_I2C2_IC_CLK_EN] = NAME(i2c2, ic),
	[A210_CLK_PERI1_I2C1_PCLK_EN] = NAME(i2c1, pclk),
	[A210_CLK_PERI1_I2C1_IC_CLK_EN] = NAME(i2c1, ic),
	[A210_CLK_PERI1_I2C0_PCLK_EN] = NAME(i2c0, pclk),
	[A210_CLK_PERI1_I2C0_IC_CLK_EN] = NAME(i2c0, ic),
	[A210_CLK_PERI1_GPIO1_PCLK_EN] = NAME(gpio1, pclk),
	[A210_CLK_PERI1_GPIO1_DBCLK_EN] = NAME(gpio1, dbclk),
	[A210_CLK_PERI1_GPIO0_PCLK_EN] = NAME(gpio0, pclk),
	[A210_CLK_PERI1_GPIO0_DBCLK_EN] = NAME(gpio0, dbclk),
	[A210_CLK_PERI1_GMAC1_HCLK_EN] = NAME(gmac1, hclk),
	[A210_CLK_PERI1_GMAC1_ACLK_EN] = NAME(gmac1, aclk),
	[A210_CLK_PERI1_GMAC0_HCLK_EN] = NAME(gmac0, hclk),
	[A210_CLK_PERI1_GMAC0_ACLK_EN] = NAME(gmac0, aclk),
	[A210_CLK_PERI2_I2S1_PCLK_EN] = NAME(i2s1, pclk),
	[A210_CLK_PERI2_I2S1_SRC_CLK_EN] = NAME(i2s1_src, NONE),
	[A210_CLK_PERI2_I2C7_IC_CLK_EN] = NAME(i2c7, ic),
	[A210_CLK_PERI2_I2C7_PCLK_EN] = NAME(i2c7, pclk),
	[A210_CLK_PERI2_I2C6_IC_CLK_EN] = NAME(i2c6, ic),
	[A210_CLK_PERI2_I2C6_PCLK_EN] = NAME(i2c6, pclk),
	[A210_CLK_PERI2_I2C5_IC_CLK_EN] = NAME(i2c5, ic),
	[A210_CLK_PERI2_I2C5_PCLK_EN] = NAME(i2c5, pclk),
	[A210_CLK_PERI2_I2C4_IC_CLK_EN] = NAME(i2c4, ic),
	[A210_CLK_PERI2_I2C4_PCLK_EN] = NAME(i2c4, pclk),
	[A210_CLK_PERI2_I2C3_IC_CLK_EN] = NAME(i2c3, ic),
	[A210_CLK_PERI2_I2C3_PCLK_EN] = NAME(i2c3, pclk),
	[A210_CLK_PERI2_GPIO3_DBCLK_EN] = NAME(gpio3, dbclk),
	[A210_CLK_PERI2_GPIO3_PCLK_EN] = NAME(gpio3, pclk),
	[A210_CLK_PERI2_SPI1_PCLK_EN] = NAME(spi1, pclk),
	[A210_CLK_PERI2_GPIO2_PCLK_EN] = NAME(gpio2, pclk),
	[A210_CLK_PERI2_SPI1_SSI_CLK_EN] = NAME(spi1, ssi),
	[A210_CLK_PERI2_GPIO2_DBCLK_EN] = NAME(gpio2, dbclk),
	[A210_CLK_PERI2_QSPI1_PCLK_EN] = NAME(qspi1, pclk),
	[A210_CLK_PERI2_QSPI1_SSI_CLK_EN] = NAME(qspi1, ssi),
	[A210_CLK_PERI2_PWM2_CCLK_EN] = NAME(pwm2, cclk),
	[A210_CLK_PERI2_PWM1_CCLK_EN] = NAME(pwm1, cclk),
	[A210_CLK_PERI3_GPIO4_PCLK_EN] = NAME(gpio4, pclk),
	[A210_CLK_PERI3_GPIO4_DBCLK_EN] = NAME(gpio4, dbclk),
	[A210_CLK_PERI3_ADC_PCLK_EN] = NAME(adc, pclk),
	[A210_CLK_AXI_PERI3_MST_PCLK_EN] = NAME(peri3_axi, pclk),
	[A210_CLK_AXI_PERI3_MST_ACLK_EN] = NAME(peri3_axi, aclk),
	[A210_CLK_PERI3_SDIO_X2X_ACLK_S_EN] = NAME(sdio_x2x, slv),
	[A210_CLK_PERI3_SDIO_X2X_ACLK_M_EN] = NAME(sdio_x2x, mst),
	[A210_CLK_PERI3_SDIO_OSC_CLK_EN] = NAME(sdio_osc, NONE),
	[A210_CLK_PERI3_SDIO_HCLK_EN] = NAME(sdio, hclk),
	[A210_CLK_PERI3_EMMC_X2X_ACLK_S_EN] = NAME(emmc_x2x, slv),
	[A210_CLK_PERI3_EMMC_X2X_ACLK_M_EN] = NAME(emmc_x2x, mst),
	[A210_CLK_PERI3_EMMC_OSC_CLK_EN] = NAME(emmc_osc, NONE),
	[A210_CLK_PERI3_EMMC_HCLK_EN] = NAME(emmc, hclk),
	[A210_CLK_PERI3_EMMC_ACLK_EN] = NAME(emmc, aclk),
	[A210_CLK_PERI3_EMMC_SDIO_REF_CLK_CG_EN] = NAME(emmc_sdio_ref, NONE),
	[A210_CLK_PERI3_DMAC_HCLK_EN] = NAME(dmac, hclk),
	[A210_CLK_PERI3_DMAC_ACLK_EN] = NAME(dmac, aclk),
	[A210_CLK_TEE_DMAC_CLKEN] = NAME(tee_dmac, NONE),
	[A210_CLK_USB20_BUS_CLK] = NAME(usb2_bus, NONE),
	[A210_CLK_PERI3_SDIO_ACLK_EN] = NAME(sdio, aclk),
	[A210_CLK_PERI1_X2H_GMAC1_HCLK_EN] = NAME(gmac1_x2h, hclk),
	[A210_CLK_PERI1_X2H_GMAC1_ACLK_EN] = NAME(gmac1_x2h, aclk),
	[A210_CLK_PERI1_X2H_GMAC0_HCLK_EN] = NAME(gmac0_x2h, hclk),
	[A210_CLK_PERI1_X2H_GMAC0_ACLK_EN] = NAME(gmac0_x2h, aclk),
	[A210_CLK_VO_HDMI_PIXCLK] = NAME(vo_hdmi, pixclk),
	[A210_CLK_USB20_X2H_HCLK] = NAME(usb2_x2h, hclk),
	[A210_CLK_USB20_X2H_ACLK] = NAME(usb2_x2h, aclk),
	[A210_CLK_USB20_SLV_AFENCE_ACLK] = NAME(usb2_af, slv),
	[A210_CLK_USB20_H2P_HCLK] = NAME(usb2_h2p, hclk),
	[A210_CLK_USB20_AHB_SLV_HCLK] = NAME(usb2_ahb, hclk),
	[A210_CLK_USB20_SYSREG_PCLK] = NAME(usb2_sys, pclk),
	[A210_CLK_USB20_WRAP0_HCLK] = NAME(usb2_wrap0, hclk),
	[A210_CLK_USB20_WRAP1_HCLK] = NAME(usb2_wrap1, hclk),
	[A210_CLK_USB20_A2X0_HCLK] = NAME(usb2_a2x0, hclk),
	[A210_CLK_USB20_A2X0_ACLK] = NAME(usb2_a2x0, aclk),
	[A210_CLK_USB20_A2X1_HCLK] = NAME(usb2_a2x1, hclk),
	[A210_CLK_USB20_A2X1_ACLK] = NAME(usb2_a2x1, aclk),
	[A210_CLK_VP_VDEC_ACLK_EN] = NAME(vdec, aclk),
	[A210_CLK_VP_VDEC_CCLK_EN] = NAME(vdec, cclk),
	[A210_CLK_VP_VDEC_PCLK_EN] = NAME(vdec, pclk),
	[A210_CLK_VP_VENC_ACLK_EN] = NAME(venc, aclk),
	[A210_CLK_VP_VENC_CCLK_EN] = NAME(venc, cclk),
	[A210_CLK_VP_VENC_PCLK_EN] = NAME(venc, pclk),
};

static const struct a210_name reset_names[] = {
	[A210_RESET_UART_SRST(0)] = NAME(uart0, NONE),
	[A210_RESET_UART_SRST(1)] = NAME(uart1, NONE),
	[A210_RESET_UART_SRST(2)] = NAME(uart2, NONE),
	[A210_RESET_UART_SRST(3)] = NAME(uart3, NONE),
	[A210_RESET_UART_SRST(4)] = NAME(uart4, NONE),
	[A210_RESET_UART_SRST(5)] = NAME(uart5, NONE),
	[A210_RESET_UART_SRST(6)] = NAME(uart6, NONE),
	[A210_RESET_UART_SRST(7)] = NAME(uart7, NONE),
	[A210_RESET_UART_SRST(8)] = NAME(uart8, NONE),
	[A210_RESET_UART_SRST(9)] = NAME(uart9, NONE),
	[A210_RESET_UART_PRST(0)] = NAME(uart0, prst),
	[A210_RESET_UART_PRST(1)] = NAME(uart1, prst),
	[A210_RESET_UART_PRST(2)] = NAME(uart2, prst),
	[A210_RESET_UART_PRST(3)] = NAME(uart3, prst),
	[A210_RESET_UART_PRST(4)] = NAME(uart4, prst),
	[A210_RESET_UART_PRST(5)] = NAME(uart5, prst),
	[A210_RESET_UART_PRST(6)] = NAME(uart6, prst),
	[A210_RESET_UART_PRST(7)] = NAME(uart7, prst),
	[A210_RESET_UART_PRST(8)] = NAME(uart8, prst),
	[A210_RESET_UART_PRST(9)] = NAME(uart9, prst),
	[A210_RESET_PERI1_PAD] = NAME(peri1_pad, NONE),
	[A210_RESET_PERI2_PAD] = NAME(peri2_pad, NONE),
	[A210_RESET_PERI3_PAD] = NAME(peri3_pad, NONE),
	[A210_RESET_AON_I2C1] = NAME(aon_i2c1, NONE),
	[A210_RESET_GPU_PWR_WRAP_RGX_HOOD_RST] = NAME(gpu, NONE),
	[A210_RESET_PCIE_DM_GEN3X4_APBS_PRST] = NAME(pcie0, apb),
	[A210_RESET_PCIE_DM_GEN3X4_POWER_UP_RST] = NAME(pcie0_pwrup, NONE),
	[A210_RESET_PCIE_E16PHY_APBS_PRST] = NAME(e16phy, apb),
	[A210_RESET_PCIE_E16PHY_PHY_RST] = NAME(e16phy, phy),
	[A210_RESET_PCIE_RP_GEN3X1_APBS_PRST] = NAME(pcie1, apb),
	[A210_RESET_PCIE_RP_GEN3X1_POWER_UP_RST] = NAME(pcie1_pwrup, NONE),
	[A210_RESET_PCIE_SATA_ARESET] = NAME(sata, arst),
	[A210_RESET_PCIE_SATA_MST_AFENCE_ARST] = NAME(sata_af, mst),
	[A210_RESET_PCIE_SATA_RST_ASIC0] = NAME(sata_asic0, NONE),
	[A210_RESET_PCIE_SATA_RST_ASIC1] = NAME(sata_asic1, NONE),
	[A210_RESET_PCIE_SATA_RST_PMALIVE] = NAME(sata_pmalive, NONE),
	[A210_RESET_PCIE_SATA_RST_RXOOB0] = NAME(sata_rxoob0, NONE),
	[A210_RESET_PCIE_SATA_RST_RXOOB1] = NAME(sata_rxoob1, NONE),
	[A210_RESET_PCIE_SATA_SLV_AFENCE_ARST] = NAME(sata_af, slv),
	[A210_RESET_PCIE_X2X_SATA_MST_ARST] = NAME(sata_x2x, mst),
	[A210_RESET_PCIE_X2X_SATA_SLV_ARST] = NAME(sata_x2x, slv),
	[A210_RESET_PERI0_TIMER0_CRST] = NAME(timer0, crst),
	[A210_RESET_PERI0_TIMER0_PRST] = NAME(timer0, prst),
	[A210_RESET_PERI0_TIMER1_CRST] = NAME(timer1, crst),
	[A210_RESET_PERI0_TIMER1_PRST] = NAME(timer1, prst),
	[A210_RESET_PERI0_WDT0_PRST] = NAME(wdt0, prst),
	[A210_RESET_PERI1_GMAC0_ARST] = NAME(gmac0, arst),
	[A210_RESET_PERI1_GMAC0_HRST] = NAME(gmac0, hrst),
	[A210_RESET_PERI1_GMAC0_X2H_ARST] = NAME(gmac0_x2h, arst),
	[A210_RESET_PERI1_GMAC0_X2H_HRST] = NAME(gmac0_x2h, hrst),
	[A210_RESET_PERI1_GMAC1_ARST] = NAME(gmac1, arst),
	[A210_RESET_PERI1_GMAC1_HRST] = NAME(gmac1, hrst),
	[A210_RESET_PERI1_GMAC1_X2H_ARST] = NAME(gmac1_x2h, arst),
	[A210_RESET_PERI1_GMAC1_X2H_HRST] = NAME(gmac1_x2h, hrst),
	[A210_RESET_PERI1_GPIO0_DBRST] = NAME(gpio0, dbrst),
	[A210_RESET_PERI1_GPIO0_PRST] = NAME(gpio0, prst),
	[A210_RESET_PERI1_GPIO1_DBRST] = NAME(gpio1, dbrst),
	[A210_RESET_PERI1_GPIO1_PRST] = NAME(gpio1, prst),
	[A210_RESET_PERI1_I2C0_IC_RST] = NAME(i2c0, ic_rst),
	[A210_RESET_PERI1_I2C0_PRST] = NAME(i2c0, prst),
	[A210_RESET_PERI1_I2C1_IC_RST] = NAME(i2c1, ic_rst),
	[A210_RESET_PERI1_I2C1_PRST] = NAME(i2c1, prst),
	[A210_RESET_PERI1_I2C2_IC_RST] = NAME(i2c2, ic_rst),
	[A210_RESET_PERI1_I2C2_PRST] = NAME(i2c2, prst),
	[A210_RESET_PERI1_PWM0_CRST] = NAME(pwm0, crst),
	[A210_RESET_PERI1_PWM0_PRST] = NAME(pwm0, prst),
	[A210_RESET_PERI1_QSPI0_PRST] = NAME(qspi0, prst),
	[A210_RESET_PERI1_QSPI0_SSI_RST] = NAME(qspi0, ssi_rst),
	[A210_RESET_PERI1_SPI0_PRST] = NAME(spi0, prst),
	[A210_RESET_PERI1_SPI0_SSI_RST] = NAME(spi0, ssi_rst),
	[A210_RESET_PERI2_GPIO2_DBRST] = NAME(gpio2, dbrst),
	[A210_RESET_PERI2_GPIO2_PRST] = NAME(gpio2, prst),
	[A210_RESET_PERI2_GPIO3_DBRST] = NAME(gpio3, dbrst),
	[A210_RESET_PERI2_GPIO3_PRST] = NAME(gpio3, prst),
	[A210_RESET_PERI2_I2C3_IC_RST] = NAME(i2c3, ic_rst),
	[A210_RESET_PERI2_I2C3_PRST] = NAME(i2c3, prst),
	[A210_RESET_PERI2_I2C4_IC_RST] = NAME(i2c4, ic_rst),
	[A210_RESET_PERI2_I2C4_PRST] = NAME(i2c4, prst),
	[A210_RESET_PERI2_I2C5_IC_RST] = NAME(i2c5, ic_rst),
	[A210_RESET_PERI2_I2C5_PRST] = NAME(i2c5, prst),
	[A210_RESET_PERI2_I2C6_IC_RST] = NAME(i2c6, ic_rst),
	[A210_RESET_PERI2_I2C6_PRST] = NAME(i2c6, prst),
	[A210_RESET_PERI2_I2C7_IC_RST] = NAME(i2c7, ic_rst),
	[A210_RESET_PERI2_I2C7_PRST] = NAME(i2c7, prst),
	[A210_RESET_PERI2_I2S1_PRST] = NAME(i2s1, prst),
	[A210_RESET_PERI2_PWM1_CRST] = NAME(pwm1, crst),
	[A210_RESET_PERI2_PWM1_PRST] = NAME(pwm1, prst),
	[A210_RESET_PERI2_PWM2_CRST] = NAME(pwm2, crst),
	[A210_RESET_PERI2_PWM2_PRST] = NAME(pwm2, prst),
	[A210_RESET_PERI2_QSPI1_PRST] = NAME(qspi1, prst),
	[A210_RESET_PERI2_QSPI1_SSI_RST] = NAME(qspi1, ssi_rst),
	[A210_RESET_PERI2_SPI1_PRST] = NAME(spi1, prst),
	[A210_RESET_PERI2_SPI1_SSI_RST] = NAME(spi1, ssi_rst),
	[A210_RESET_PERI3_ADC_PRST] = NAME(adc, prst),
	[A210_RESET_PERI3_DMAC_ARST] = NAME(dmac, arst),
	[A210_RESET_PERI3_DMAC_HRST] = NAME(dmac, hrst),
	[A210_RESET_PERI3_EMMC_RST] = NAME(emmc, rst),
	[A210_RESET_PERI3_EMMC_X2X_ARST_M] = NAME(emmc_x2x, mst),
	[A210_RESET_PERI3_EMMC_X2X_ARST_S] = NAME(emmc_x2x, slv),
	[A210_RESET_PERI3_GPIO4_DBRST] = NAME(gpio4, dbrst),
	[A210_RESET_PERI3_GPIO4_PRST] = NAME(gpio4, prst),
	[A210_RESET_PERI3_SDIO_RST] = NAME(sdio, rst),
	[A210_RESET_PERI3_SDIO_X2X_ARST_M] = NAME(sdio_x2x, mst),
	[A210_RESET_PERI3_SDIO_X2X_ARST_S] = NAME(sdio_x2x, slv),
	[A210_RESET_TEE_DMAC_ARST] = NAME(tee_dmac, arst),
	[A210_RESET_TEE_DMAC_HRST] = NAME(tee_dmac, hrst),
	[A210_RESET_USB_AXI4_MST_ARST] = NAME(usbss_axi, arst),
	[A210_RESET_USB_AXI4_MST_PRST] = NAME(usbss_axi, prst),
	[A210_RESET_USB_C10PHY_APBS_PRST] = NAME(c10phy, apb),
	[A210_RESET_USB_C10PHY_PHY_RST] = NAME(c10phy, phy),
	[A210_RESET_USB_DFMU_ARST] = NAME(usbss_dfmu, arst),
	[A210_RESET_USB_DFMU_PRST] = NAME(usbss_dfmu, prst),
	[A210_RESET_USB_USB20_BLK_A2X0_ARST] = NAME(usb2_a2x0, arst),
	[A210_RESET_USB_USB20_BLK_A2X0_HRST] = NAME(usb2_a2x0, hrst),
	[A210_RESET_USB_USB20_BLK_A2X1_ARST] = NAME(usb2_a2x1, arst),
	[A210_RESET_USB_USB20_BLK_A2X1_HRST] = NAME(usb2_a2x1, hrst),
	[A210_RESET_USB_USB20_BLK_AHB_SLV_HRST] = NAME(usb2_ahb, hrst),
	[A210_RESET_USB_USB20_BLK_AXI_MST_ARST] = NAME(usb2_axi, arst),
	[A210_RESET_USB_USB20_BLK_H2P_HRST] = NAME(usb2_h2p, hrst),
	[A210_RESET_USB_USB20_BLK_USB0_PHY_PON_RESET] = NAME(usb2_phy0, NONE),
	[A210_RESET_USB_USB20_BLK_USB1_PHY_PON_RESET] = NAME(usb2_phy1, NONE),
	[A210_RESET_USB_USB20_BLK_USB2_SYSREG_PRST] = NAME(usb2_sys, prst),
	[A210_RESET_USB_USB20_BLK_USB2_WRAP0_HRST] = NAME(usb2_wrap0, hrst),
	[A210_RESET_USB_USB20_BLK_USB2_WRAP0_PRST] = NAME(usb2_wrap0, prst),
	[A210_RESET_USB_USB20_BLK_USB2_WRAP1_HRST] = NAME(usb2_wrap1, hrst),
	[A210_RESET_USB_USB20_BLK_USB2_WRAP1_PRST] = NAME(usb2_wrap1, prst),
	[A210_RESET_USB_USB20_BLK_X2H_ARST] = NAME(usb2_x2h, arst),
	[A210_RESET_USB_USB20_BLK_X2H_HRST] = NAME(usb2_x2h, hrst),
	[A210_RESET_USB_USB20_SLV_AFENCE_ARST] = NAME(usb2_af, slv),
	[A210_RESET_USB_USB31_APBS_PRST] = NAME(usb3, apb),
	[A210_RESET_USB_USB31_PHY_RST] = NAME(usb3, phy),
	[A210_RESET_USB_USB31_SLV_AFENCE_ARST] = NAME(usb3_af, slv),
	[A210_RESET_USB_USB31_VCC_RST] = NAME(usb3_vcc, rst),
	[A210_RESET_VO_ARB_ARST] = NAME(vo_arb, arst),
	[A210_RESET_VO_ARB_PRST] = NAME(vo_arb, prst),
	[A210_RESET_VO_DFMU_ARST] = NAME(vo_dfmu, arst),
	[A210_RESET_VO_DFMU_PRST] = NAME(vo_dfmu, prst),
	[A210_RESET_VO_DPU_ARST] = NAME(vo_dpu, arst),
	[A210_RESET_VO_DPU_CRST] = NAME(vo_dpu, crst),
	[A210_RESET_VO_DPU_HRST] = NAME(vo_dpu, hrst),
	[A210_RESET_VO_HDMI_MAIN_RST] = NAME(vo_hdmi, rst),
	[A210_RESET_VO_HDMI_PRST] = NAME(vo_hdmi, prst),
	[A210_RESET_VO_X2H0_RST] = NAME(vo_x2h0, rst),
	[A210_RESET_VO_X2H1_RST] = NAME(vo_x2h1, rst),
	[A210_RESET_VP_VDEC_PRST] = NAME(vdec, prst),
	[A210_RESET_VP_VDEC_CRST] = NAME(vdec, crst),
	[A210_RESET_VP_VDEC_ARST] = NAME(vdec, arst),
	[A210_RESET_VP_VENC_PRST] = NAME(venc, prst),
	[A210_RESET_VP_VENC_CRST] = NAME(venc, crst),
	[A210_RESET_VP_VENC_ARST] = NAME(venc, arst),
	[A210_RESET_VP_COMP_PRST] = NAME(comp, prst),
	[A210_RESET_VP_COMP_CRST] = NAME(comp, crst),
	[A210_RESET_VP_COMP_ARST] = NAME(comp, arst),
	[A210_RESET_VP_DECOMP_PRST] = NAME(decomp, prst),
	[A210_RESET_VP_DECOMP_CRST] = NAME(decomp, crst),
	[A210_RESET_VP_DECOMP_ARST] = NAME(decomp, arst),
	[A210_RESET_VP_COMP_EXTPRST] = NAME(comp_ext, NONE),
	[A210_RESET_VP_DECOMP_EXTPRST] = NAME(decomp_ext, NONE),
};

#endif /* A210_NAMES_H_ */
```

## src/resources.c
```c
/* SPDX-License-Identifier: Apache-2.0 */
#include <zephyr/device.h>
#include <zephyr/drivers/clock_control.h>
#include <zephyr/drivers/reset.h>
#include <zephyr/mgmt/scmi/clock.h>
#include <zephyr/mgmt/scmi/reset.h>
#include "resources.h"

#define USER DT_PATH(zephyr_user)

#if defined(CONFIG_SCMI_SERVER_CLOCK) && DT_NODE_HAS_PROP(USER, clocks)
struct clock_resource {
	const struct device *dev;
	uintptr_t id;
};

static int get_rate(void *context, uint64_t *rate)
{
	const struct clock_resource *r = context;
	uint32_t hz;
	int ret = clock_control_get_rate(r->dev, (void *)r->id, &hz);

	if (!ret) {
		*rate = hz;
	}
	return ret;
}

static int describe_rate(void *context, unsigned int index, uint64_t *rate)
{
	return index ? -EINVAL : get_rate(context, rate);
}

static int get_enabled(void *context, bool *enabled)
{
	const struct clock_resource *r = context;
	enum clock_control_status state = clock_control_get_status(r->dev, (void *)r->id);

	if (state != CLOCK_CONTROL_STATUS_ON && state != CLOCK_CONTROL_STATUS_OFF) {
		return -EIO;
	}
	*enabled = state == CLOCK_CONTROL_STATUS_ON;
	return 0;
}

static int set_enabled(void *context, bool enabled)
{
	const struct clock_resource *r = context;

	return enabled ? clock_control_on(r->dev, (void *)r->id) :
			 clock_control_off(r->dev, (void *)r->id);
}

static const struct scmi_clock_ops clock_ops = {
	.get_rate = get_rate,
	.describe_rate = describe_rate,
	.get_enabled = get_enabled,
	.set_enabled = set_enabled,
};

#define CLOCK_RESOURCE(node, prop, i) \
	{DEVICE_DT_GET(DT_CLOCKS_CTLR_BY_IDX(node, i)), DT_CLOCKS_CELL_BY_IDX(node, i, id)},
static const struct clock_resource clock_resources[] = {
	DT_FOREACH_PROP_ELEM(USER, clocks, CLOCK_RESOURCE)};

#define CLOCK_DOMAIN(node, prop, i) \
	{.name = DT_PROP_BY_IDX(node, clock_names, i), .context = (void *)&clock_resources[i], \
	 .ops = &clock_ops, .rate_count = 1},
static const struct scmi_clock clocks[] = {DT_FOREACH_PROP_ELEM(USER, clocks, CLOCK_DOMAIN)};
#endif

#if defined(CONFIG_SCMI_SERVER_RESET) && DT_NODE_HAS_PROP(USER, resets)
static int set_asserted(void *context, bool asserted)
{
	const struct reset_dt_spec *r = context;

	return asserted ? reset_line_assert_dt(r) : reset_line_deassert_dt(r);
}

#define RESET_RESOURCE(node, prop, i) RESET_DT_SPEC_GET_BY_IDX(node, i),
static const struct reset_dt_spec reset_resources[] = {
	DT_FOREACH_PROP_ELEM(USER, resets, RESET_RESOURCE)};

#define RESET_DOMAIN(node, prop, i) \
	{.name = DT_PROP_BY_IDX(node, reset_names, i), .context = (void *)&reset_resources[i], \
	 .latency_us = UINT32_MAX, .set_asserted = set_asserted},
static const struct scmi_reset_domain resets[] = {
	DT_FOREACH_PROP_ELEM(USER, resets, RESET_DOMAIN)};
#endif

void scmi_resources_poll(void)
{
}

int scmi_resources_init(struct scmi_server *server)
{
	ARG_UNUSED(server);
#if defined(CONFIG_SCMI_SERVER_CLOCK) && DT_NODE_HAS_PROP(USER, clocks)
	for (size_t i = 0; i < ARRAY_SIZE(clock_resources); i++) {
		if (!device_is_ready(clock_resources[i].dev)) {
			return -ENODEV;
		}
	}
	server->clocks = clocks;
	server->clock_count = ARRAY_SIZE(clocks);
#endif
#if defined(CONFIG_SCMI_SERVER_RESET) && DT_NODE_HAS_PROP(USER, resets)
	for (size_t i = 0; i < ARRAY_SIZE(reset_resources); i++) {
		if (!device_is_ready(reset_resources[i].dev)) {
			return -ENODEV;
		}
	}
	server->reset_domains = resets;
	server->reset_count = ARRAY_SIZE(resets);
#endif
	return 0;
}
```

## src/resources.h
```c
/* SPDX-License-Identifier: Apache-2.0 */
#ifndef SCMI_SAMPLE_RESOURCES_H_
#define SCMI_SAMPLE_RESOURCES_H_

#include <zephyr/mgmt/scmi/server.h>

int scmi_resources_init(struct scmi_server *server);
/* Periodic platform work from the firmware's polling loop. */
void scmi_resources_poll(void);

#endif
```
